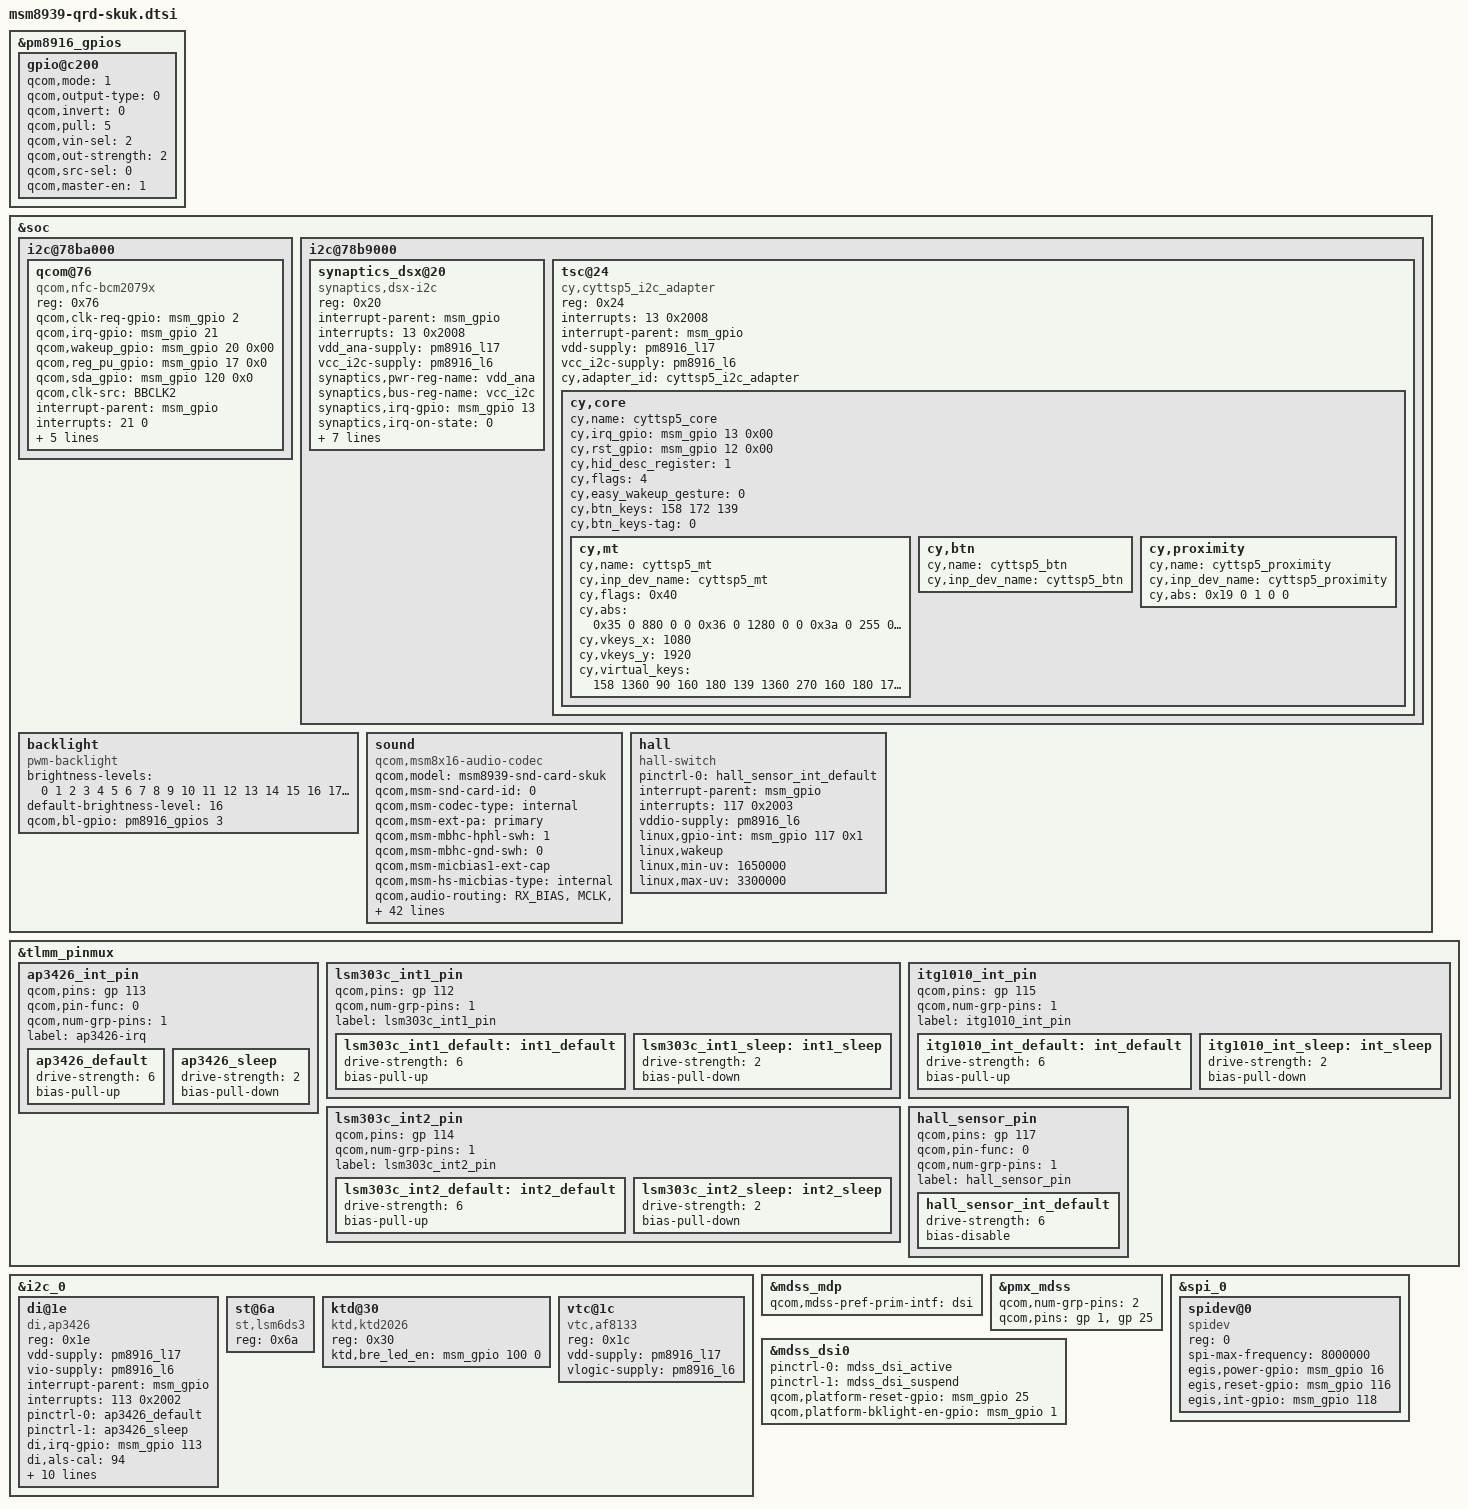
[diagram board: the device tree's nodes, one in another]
/* Copyright (c) 2014-2015, The Linux Foundation. All rights reserved.
 *
 * This program is free software; you can redistribute it and/or modify
 * it under the terms of the GNU General Public License version 2 and
 * only version 2 as published by the Free Software Foundation.
 *
 * This program is distributed in the hope that it will be useful,
 * but WITHOUT ANY WARRANTY; without even the implied warranty of
 * MERCHANTABILITY or FITNESS FOR A PARTICULAR PURPOSE.  See the
 * GNU General Public License for more details.
 */

#include "msm8939-qrd.dtsi"
#include "msm8939-camera-sensor-qrd.dtsi"

/* zhangwei add for backlight gpio3 */
&pm8916_gpios {
   	gpio@c200 { /* GPIO 3 */
	 	/* backlight ctrl */
		qcom,mode = <1>; /* QPNP_PIN_MODE_DIG_IN */
		qcom,output-type = <0>; /* QPNP_PIN_OUT_BUF_CMOS */
		qcom,invert = <0>;
		qcom,pull = <5>; /* QPNP_PIN_PULL_NO */
		qcom,vin-sel = <2>; /* QPNP_PIN_VIN2 */
		qcom,out-strength = <2>; /* QPNP_PIN_OUT_STRENGTH_MED */
		qcom,src-sel = <0>; /* QPNP_PIN_SEL_FUNC_0 */
		qcom,master-en = <1>;
	};  
};

&soc {
	i2c@78ba000 {
		/*chenjian add for sq9007 psensor and lsensor start*/
		/*
		stk@48 {
			compatible = "stk,stk3x1x";
			reg = <0x48>;
			interrupt-parent = <&msm_gpio>;
			interrupts = <113 0x2002>;
			vdd-supply = <&pm8916_l17>;
			stk,irq-gpio = <&msm_gpio 113 0x2002>;
			stk,state-reg = <0x0>;
			stk,psctrl-reg = <0x31>;
			stk,alsctrl-reg = <0x38>;
			stk,ledctrl-reg = <0xFF>;
			stk,wait-reg = <0x07>;
			stk,ps-thdh = <1700>;
			stk,ps-thdl = <1500>;
			stk,transmittance = <500>;
			stk,use-fir;
		};
*/

		qcom@76 {
			compatible = "qcom,nfc-bcm2079x";
			reg = <0x76>;
			qcom,clk-req-gpio = <&msm_gpio 2 0x00>;
			qcom,irq-gpio = <&msm_gpio 21 0x00>;
			qcom,wakeup_gpio = <&msm_gpio 20 0x00>;
			qcom,reg_pu_gpio = <&msm_gpio 17 0x0>;	
			qcom,sda_gpio = <&msm_gpio 120 0x0>;	//Add test code
			qcom,clk-src = "BBCLK2";
			interrupt-parent = <&msm_gpio>;
			interrupts = <21 0>;
			interrupt-names = "nfc_irq";
			pinctrl-names = "nfc_active","nfc_suspend";
			pinctrl-0 = <&nfc_int_active &nfc_disable_active &nfc_reg_pu_active>;
			pinctrl-1 = <&nfc_int_suspend &nfc_disable_suspend &nfc_reg_pu_suspend>;
		  	clocks = <&clock_rpm clk_bb_clk2_pin>;
		  	clock-names = "ref_clk";
		};
	};

	i2c@78b9000 { /* BLSP1 QUP5 */
		/*focaltech@38 {
			compatible = "focaltech,5x06";
			reg = <0x38>;
			interrupt-parent = <&msm_gpio>;
			interrupts = <13 0x2008>;
			vdd-supply = <&pm8916_l17>;
			vcc_i2c-supply = <&pm8916_l6>;
			pinctrl-names = "pmx_ts_active","pmx_ts_suspend","pmx_ts_release";
			pinctrl-0 = <&ts_int_active &ts_reset_active>;
			pinctrl-1 = <&ts_int_suspend &ts_reset_suspend>;
			pinctrl-2 = <&ts_release>;
			focaltech,name = "ft5336";
			focaltech,family-id = <0x14>;
			focaltech,reset-gpio = <&msm_gpio 12 0x0>;
			focaltech,irq-gpio = <&msm_gpio 13 0x2008>;
			focaltech,display-coords = <0 0 1080 1920>;
			focaltech,panel-coords = <0 0 1080 2098>;
			focaltech,button-map= <139 102 158>;
			focaltech,no-force-update;
			focaltech,i2c-pull-up;
			focaltech,group-id = <1>;
			focaltech,hard-reset-delay-ms = <20>;
			focaltech,soft-reset-delay-ms = <200>;
			focaltech,num-max-touches = <5>;
			focaltech,fw-delay-aa-ms = <30>;
			focaltech,fw-delay-55-ms = <30>;
			focaltech,fw-upgrade-id1 = <0x11>;
			focaltech,fw-upgrade-id2 = <0x11>;
			focaltech,fw-delay-readid-ms = <10>;
			focaltech,fw-delay-era-flsh-ms = <2000>;
			focaltech,fw-auto-cal;
			focaltech,ignore-id-check;
		};*/
/*added by zougaoxiang@hipad.com for sq9007 2014/10/28/20:08 start*/
	synaptics_dsx@20 {
		compatible = "synaptics,dsx-i2c";
		reg = <0x20>;
		interrupt-parent = <&msm_gpio>;
		interrupts = <13 0x2008>;
		vdd_ana-supply = <&pm8916_l17>;
		vcc_i2c-supply = <&pm8916_l6>;
		synaptics,pwr-reg-name = "vdd_ana";
		synaptics,bus-reg-name = "vcc_i2c";
		synaptics,irq-gpio = <&msm_gpio 13 0x00>;
		synaptics,irq-on-state = <0>;
		synaptics,irq-flags = <0x2008>; /* IRQF_ONESHOT | IRQF_TRIGGER_LOW */
		synaptics,reset-gpio = <&msm_gpio 12 0x00>;
		synaptics,power-delay-ms = <200>;
		synaptics,reset-delay-ms = <200>;
		synaptics,max-y-for-2d = <800>; /* remove if no virtual buttons */			
		synaptics,vir-button-codes = <102 100 900 100 60 158 300 900 100 60>;		
		};
		
	tsc@24 {
			compatible = "cy,cyttsp5_i2c_adapter";
			reg = <0x24>;
			interrupts = <13 0x2008>;
			interrupt-parent = <&msm_gpio>;
			vdd-supply = <&pm8916_l17>;
			vcc_i2c-supply = <&pm8916_l6>;
			cy,adapter_id = "cyttsp5_i2c_adapter";
			cy,core {
				cy,name = "cyttsp5_core";
				
				cy,irq_gpio = <&msm_gpio 13 0x00>;
				cy,rst_gpio = <&msm_gpio 12 0x00>;
				cy,hid_desc_register = <1>;

				/* CY_CORE_FLAG_WAKE_ON_GESTURE */
				cy,flags = <4>;

				/* CY_CORE_EWG_TAP_TAP | CY_CORE_EWG_TWO_FINGER_SLIDE */
				cy,easy_wakeup_gesture = <0>;
                                cy,btn_keys = <158 /* KEY_MENU */
                                               172 /* KEY_HOME */
                                               139>; /* KEY_BACK */
							   
				cy,btn_keys-tag = <0>;

				cy,mt {
					cy,name = "cyttsp5_mt";
					cy,inp_dev_name = "cyttsp5_mt";
					/* CY_MT_FLAG_FLIP | CY_MT_FLAG_INV_X | CY_MT_FLAG_INV_Y */
					cy,flags = <0x40>;
					cy,abs =
						/* ABS_MT_POSITION_X, CY_ABS_MIN_X, CY_ABS_MAX_X, 0, 0 */
						<0x35 0 880 0 0
						/* ABS_MT_POSITION_Y, CY_ABS_MIN_Y, CY_ABS_MAX_Y, 0, 0 */
						0x36 0 1280 0 0
						/* ABS_MT_PRESSURE, CY_ABS_MIN_P, CY_ABS_MAX_P, 0, 0 */
						0x3a 0 255 0 0
						/* CY_IGNORE_VALUE, CY_ABS_MIN_W, CY_ABS_MAX_W, 0, 0 */
						0xffff 0 255 0 0
						/* ABS_MT_TRACKING_ID, CY_ABS_MIN_T, CY_ABS_MAX_T, 0, 0 */
						0x39 0 15 0 0
						/* ABS_MT_TOUCH_MAJOR, 0, 255, 0, 0 */
						0x30 0 255 0 0
						/* ABS_MT_TOUCH_MINOR, 0, 255, 0, 0 */
						0x31 0 255 0 0
						/* ABS_MT_ORIENTATION, -127, 127, 0, 0 */
						0x34 0xffffff81 127 0 0
						/* ABS_MT_TOOL_TYPE, 0, MT_TOOL_MAX, 0, 0 */
						0x37 0 1 0 0
						/* ABS_DISTANCE, 0, 255, 0, 0 */
						0x19 0 255 0 0>;

					cy,vkeys_x = <1080>;
					cy,vkeys_y = <1920>;
					cy,virtual_keys = /* KeyCode CenterX CenterY Width Height */
						/* KEY_BACK */
						<158 1360 90 160 180
						/* KEY_MENU */
						139 1360 270 160 180
						/* KEY_HOMEPAGE */
						172 1360 450 160 180
						/* KEY SEARCH */
						217 1360 630 160 180>;
				};
				cy,btn {
					cy,name = "cyttsp5_btn";
					cy,inp_dev_name = "cyttsp5_btn";
				};
				cy,proximity {
					cy,name = "cyttsp5_proximity";

					cy,inp_dev_name = "cyttsp5_proximity";
					cy,abs =
						/* ABS_DISTANCE, CY_PROXIMITY_MIN_VAL, CY_PROXIMITY_MAX_VAL, 0, 0 */
						<0x19 0 1 0 0>;
				};				
			};
		};
/*added by zougaoxiang@hipad.com for sq9007 2014/10/28/20:08 end*/
	};
/*
	gen-vkeys {
		compatible = "qcom,gen-vkeys";
		label = "ft5x06_ts";
		qcom,disp-maxx = <1080>;
		qcom,disp-maxy = <1920>;
		qcom,panel-maxx = <1080>;
		qcom,panel-maxy = <2098>;
		qcom,key-codes = <139 172 158>;
		qcom,y-offset = <0>;
	};
*/
/*xiesu add for one-line-mode-backlight 20150317*/
	backlight {
		compatible = "pwm-backlight";
		brightness-levels = <0 1 2 3 4 5 6 7 8 9 10 11 12 13 14 15 16 17 18 19 20 21 22 23 24 25 26 27 28 29 30 31 32>;
		default-brightness-level = <16>;
		qcom,bl-gpio = <&pm8916_gpios 3 0>;
	}; 
	sound {
		compatible = "qcom,msm8x16-audio-codec";
		qcom,model = "msm8939-snd-card-skuk";
		qcom,msm-snd-card-id = <0>;
		qcom,msm-codec-type = "internal";
		qcom,msm-ext-pa = "primary";
		qcom,msm-mbhc-hphl-swh = <1>;
		qcom,msm-mbhc-gnd-swh = <0>;
		qcom,msm-micbias1-ext-cap;
		qcom,msm-hs-micbias-type = "internal";
		qcom,audio-routing =
			"RX_BIAS", "MCLK",
			"SPK_RX_BIAS", "MCLK",
			"INT_LDO_H", "MCLK",
			"MIC BIAS External", "Handset Mic",
			"MIC BIAS Internal2", "Headset Mic",
			"MIC BIAS External", "Secondary Mic",
			"AMIC1", "MIC BIAS External",
			"AMIC2", "MIC BIAS Internal2",
			"AMIC3", "MIC BIAS External";
		pinctrl-names = "cdc_lines_act",
				"cdc_lines_sus";
		pinctrl-0 = <&cdc_pdm_lines_act>;
		pinctrl-1 = <&cdc_pdm_lines_sus>;
		qcom,ext-spk-amp-gpio = <&msm_gpio 0 0>;
		asoc-platform = <&pcm0>, <&pcm1>, <&voip>, <&voice>,
				<&loopback>, <&compress>, <&hostless>,
				<&afe>, <&lsm>, <&routing>, <&lpa>;
		asoc-platform-names = "msm-pcm-dsp.0", "msm-pcm-dsp.1",
				"msm-voip-dsp", "msm-pcm-voice", "msm-pcm-loopback",
				"msm-compress-dsp", "msm-pcm-hostless", "msm-pcm-afe",
				"msm-lsm-client", "msm-pcm-routing", "msm-pcm-lpa";
		asoc-cpu = <&dai_pri_auxpcm>, <&dai_hdmi>, <&dai_mi2s0>, <&dai_mi2s1>,
				<&dai_mi2s2>, <&dai_mi2s3>, <&sb_0_rx>, <&sb_0_tx>,
				<&sb_1_rx>, <&sb_1_tx>, <&sb_3_rx>, <&sb_3_tx>,
				<&sb_4_rx>, <&sb_4_tx>, <&sb_5_tx>, <&bt_sco_rx>,
				<&bt_sco_tx>, <&int_fm_rx>, <&int_fm_tx>, <&afe_pcm_rx>,
				<&afe_pcm_tx>, <&afe_proxy_rx>, <&afe_proxy_tx>,
				<&incall_record_rx>, <&incall_record_tx>, <&incall_music_rx>,
				<&incall_music_2_rx>;
		asoc-cpu-names = "msm-dai-q6-auxpcm.1", "msm-dai-q6-hdmi.8", "msm-dai-q6-mi2s.0",
				"msm-dai-q6-mi2s.1", "msm-dai-q6-mi2s.2",
				"msm-dai-q6-mi2s.3", "msm-dai-q6-dev.16384",
				"msm-dai-q6-dev.16385", "msm-dai-q6-dev.16386",
				"msm-dai-q6-dev.16387", "msm-dai-q6-dev.16390",
				"msm-dai-q6-dev.16391", "msm-dai-q6-dev.16392",
				"msm-dai-q6-dev.16393", "msm-dai-q6-dev.16395",
				"msm-dai-q6-dev.12288", "msm-dai-q6-dev.12289",
				"msm-dai-q6-dev.12292", "msm-dai-q6-dev.12293",
				"msm-dai-q6-dev.224", "msm-dai-q6-dev.225",
				"msm-dai-q6-dev.241", "msm-dai-q6-dev.240",
				"msm-dai-q6-dev.32771", "msm-dai-q6-dev.32772",
				"msm-dai-q6-dev.32773", "msm-dai-q6-dev.32770";
		asoc-codec = <&stub_codec>, <&pm8916_tombak_dig>;
		asoc-codec-names = "msm-stub-codec.1", "tombak_codec";
	};
	
	/*lijinpei add for hall sensor*/
    hall {
        compatible = "hall-switch";
        pinctrl-names = "default";
        pinctrl-0 = <&hall_sensor_int_default>;
        interrupt-parent = <&msm_gpio>;
        interrupts = <117 0x2003>;
        vddio-supply = <&pm8916_l6>;
        linux,gpio-int = <&msm_gpio 117 0x1>;
        linux,wakeup;
        linux,min-uv = <1650000>;
        linux,max-uv = <3300000>;
    };
};


&tlmm_pinmux {
/*
	bma2x2_int1_pin {
		qcom,pins = <&gp 112>;
		qcom,num-grp-pins = <1>;
		label = "bma2x2_int1_pin";
		bma2x2_int1_default: int1_default {
			  drive-strength = <6>;
			  bias-pull-up;
		};
		bma2x2_int1_sleep: int1_sleep {
			  drive-strength = <2>;
			  bias-pull-down;
		};
	};

	bma2x2_int2_pin {
		qcom,pins = <&gp 114>;
		qcom,num-grp-pins = <1>;
		label = "bma2x2_int2_pin";
		bma2x2_int2_default: int2_default {
			  drive-strength = <6>;
			  bias-pull-up;
		};
		bma2x2_int2_sleep: int2_sleep {
			  drive-strength = <2>;
			  bias-pull-down;
		};
	};
*/

	ap3426_int_pin {
                qcom,pins = <&gp 113>;
                qcom,pin-func = <0>;
                qcom,num-grp-pins = <1>;
                label = "ap3426-irq";
                ap3426_default: ap3426_default {
                        drive-strength = <6>;
                        bias-pull-up;
                };
                ap3426_sleep: ap3426_sleep {
                        drive-strength = <2>;
                        bias-pull-down;
                };
        };
	lsm303c_int1_pin {
	    qcom,pins = <&gp 112>;
		qcom,num-grp-pins = <1>;
		label = "lsm303c_int1_pin";
		lsm303c_int1_default: int1_default {
			drive-strength = <6>;
			bias-pull-up;
		};
		lsm303c_int1_sleep: int1_sleep {
			drive-strength = <2>;
			bias-pull-down;
		};
	};
	
	lsm303c_int2_pin {
		qcom,pins = <&gp 114>;
		qcom,num-grp-pins = <1>;
		label = "lsm303c_int2_pin";
		lsm303c_int2_default: int2_default {
			drive-strength = <6>;
			bias-pull-up;
		};
		lsm303c_int2_sleep: int2_sleep {
			drive-strength = <2>;
			bias-pull-down;
		};
	};

	itg1010_int_pin {
		qcom,pins = <&gp 115>;
		qcom,num-grp-pins = <1>;
		label = "itg1010_int_pin";
		itg1010_int_default: int_default {
			drive-strength = <6>;
			bias-pull-up;
		};
		itg1010_int_sleep: int_sleep {
			drive-strength = <2>;
			bias-pull-down;
		};	
	};
	/* lijinpei add hall sensor int-pin */
	hall_sensor_pin {
		qcom,pins = <&gp 117>;
		qcom,pin-func = <0>;
		qcom,num-grp-pins = <1>;
		label = "hall_sensor_pin";
		hall_sensor_int_default: hall_sensor_int_default {
			drive-strength = <6>;
			bias-disable;
		};
	};
};

&i2c_0 { /* BLSP1 QUP2 */

	di@1e {
    compatible = "di,ap3426";
    reg = <0x1e>;
    vdd-supply = <&pm8916_l17>;
    vio-supply = <&pm8916_l6>;
    interrupt-parent = <&msm_gpio>;
    interrupts = <113 0x2002>;
    pinctrl-names = "default","sleep";
    pinctrl-0 = <&ap3426_default>;
    pinctrl-1 = <&ap3426_sleep>;
    di,irq-gpio = <&msm_gpio 113 0x2002>;
    di,als-cal = <94>;
    di,als-gain = <0>;
    di,als-persist = <1>;
    di,ps-gain = <1>;
    di,ps-persist = <2>;
    di,ps-led-driver = <3>;
    di,ps-mean-time = <0>;
    di,ps-integrated-time = <0>;
    /*di,ps-distance-table = <887 282 111 78 53 46>;*/
    di,ps-distance-table = < 887 500 400 300 200 100>;
    di,als-sensitivity = <50>;
    di,wakeup-threshold = <4>;
  };
  
	st@6a {
		compatible = "st,lsm6ds3";
		reg = <0x6a>;
	};

	ktd@30 { /* breath led */
		compatible = "ktd,ktd2026";
		reg = <0x30>;
        /*ktd,home_key_en = <&msm_gpio 3 0>;*/
        ktd,bre_led_en = <&msm_gpio 100 0>;

	};	
	
	vtc@1c {/*Magnetic sensor*/
		compatible = "vtc,af8133";
                reg = <0x1c>;
		vdd-supply = <&pm8916_l17>;
                vlogic-supply = <&pm8916_l6>;
		
       };
};

/*chenjian
&sdc2_cd_on {
	/delete-property/ bias-pull-up;
	bias-pull-down;
};

&sdc2_cd_off {
	/delete-property/ bias-disable;
	bias-pull-down;
};

&sdhc_2 {
	qcom,nonhotplug;
	interrupts = <0 1>;
	interrupt-map = <0 &intc 0 125 0
		1 &intc 0 221 0>;
	interrupt-names = "hc_irq", "pwr_irq";
	/delete-property/ cd-gpios;
};
*/

&mdss_mdp {
	qcom,mdss-pref-prim-intf = "dsi";
};

&pmx_mdss {
	qcom,num-grp-pins = <2>;
	qcom,pins = <&gp 1>, <&gp 25>;
};

&mdss_dsi0 {
	pinctrl-names = "mdss_default", "mdss_sleep";
	pinctrl-0 = <&mdss_dsi_active>;
	pinctrl-1 = <&mdss_dsi_suspend>;

	qcom,platform-reset-gpio = <&msm_gpio 25 0>;
	qcom,platform-bklight-en-gpio = <&msm_gpio 1 0>;
};

/*zhongzhu add for fringerprint*/
&spi_0{
			spidev@0 {
			compatible = "spidev";
			reg = <0>;
			spi-max-frequency = <8000000>;
			egis,power-gpio = <&msm_gpio 16 0>;
			egis,reset-gpio = <&msm_gpio 116 0>;
			egis,int-gpio = <&msm_gpio 118 0>;
		};
};
